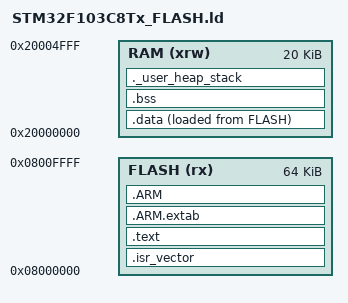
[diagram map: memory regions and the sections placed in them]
ENTRY(Reset_Handler)

MEMORY
{
  FLASH (rx) : ORIGIN = 0x08000000, LENGTH = 64K
  RAM (xrw)  : ORIGIN = 0x20000000, LENGTH = 20K
}

_estack = ORIGIN(RAM) + LENGTH(RAM);

SECTIONS
{
  .isr_vector :
  {
    KEEP(*(.isr_vector))
  } > FLASH

  .text :
  {
    *(.text)
    *(.text*)
    *(.glue_7)
    *(.glue_7t)
    *(.eh_frame)
    KEEP(*(.init))
    KEEP(*(.fini))
    *(.rodata)
    *(.rodata*)
  } > FLASH

  .ARM.extab :
  {
    *(.ARM.extab* .gnu.linkonce.armextab.*)
  } > FLASH

  .ARM :
  {
    __exidx_start = .;
    *(.ARM.exidx*)
    __exidx_end = .;
  } > FLASH

  _sidata = LOADADDR(.data);

  .data :
  {
    . = ALIGN(4);
    _sdata = .;
    *(.data)
    *(.data*)
    . = ALIGN(4);
    _edata = .;
  } > RAM AT > FLASH

  .bss :
  {
    . = ALIGN(4);
    _sbss = .;
    __bss_start__ = _sbss;
    *(.bss)
    *(.bss*)
    *(COMMON)
    . = ALIGN(4);
    _ebss = .;
    __bss_end__ = _ebss;
  } > RAM

  ._user_heap_stack :
  {
    . = ALIGN(8);
    PROVIDE(end = .);
    PROVIDE(_end = .);
    . = . + 0x400;
    . = . + 0x400;
    . = ALIGN(8);
  } > RAM

  /DISCARD/ :
  {
    libc.a(*)
    libm.a(*)
    libgcc.a(*)
  }
}
